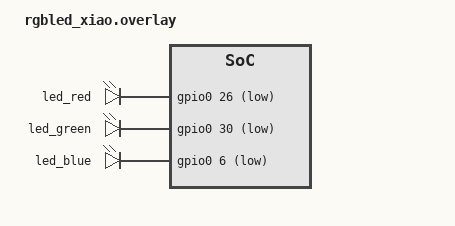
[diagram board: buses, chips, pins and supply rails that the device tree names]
/ {
    leds {
        compatible = "gpio-leds";

        led_red: led_red {
            gpios = <&gpio0 26 GPIO_ACTIVE_LOW>;
        };

        led_green: led_green {
            gpios = <&gpio0 30 GPIO_ACTIVE_LOW>;
        };

        led_blue: led_blue {
            gpios = <&gpio0 6 GPIO_ACTIVE_LOW>;
        };
    };

    aliases {
        led-red = &led_red;
        led-green = &led_green;
        led-blue = &led_blue;
    };
};

